VERSION ""

NS_ :

BS_:

BU_: DUT

BO_ 2365512363 MSG_DUT_FEDA: 16 DUT

BO_ 2558590718 MSG_DUT_8000: 8 DUT

BO_ 2559639294 MSG_DUT_9000: 52 DUT

BO_ 2365516715 MSG_DUT_COMP_ID: 13 DUT
 SG_ Component_ID_Delim_4 : 88|8@1+ (1,0) [0|65535] "" Vector__XXX
 SG_ Component_ID_Data_4 : 72|16@1+ (1,0) [0|65535] "" Vector__XXX
 SG_ Component_ID_Delim_3 : 64|8@1+ (1,0) [0|65535] "" Vector__XXX
 SG_ Component_ID_Data_3 : 48|16@1+ (1,0) [0|65535] "" Vector__XXX
 SG_ Component_ID_Delim_2 : 40|8@1+ (1,0) [0|65535] "" Vector__XXX
 SG_ Component_ID_Data_2 : 24|16@1+ (1,0) [0|65535] "" Vector__XXX
 SG_ Component_ID_Delim_1 : 16|8@1+ (1,0) [0|65535] "" Vector__XXX
 SG_ Component_ID_Data_1 : 0|16@1+ (1,0) [0|65535] "" Vector__XXX

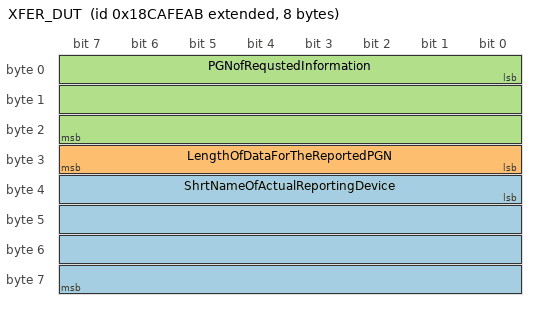
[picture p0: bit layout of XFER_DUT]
BO_ 2563440299 XFER_DUT: 8 DUT
 SG_ ShrtNameOfActualReportingDevice : 32|32@1+ (1,0) [0|0] "" Vector__XXX
 SG_ LengthOfDataForTheReportedPGN : 24|8@1+ (1,0) [0|255] "" Vector__XXX
 SG_ PGNofRequstedInformation : 0|24@1+ (1,0) [0|16777215] "" Vector__XXX

BO_ 2566834937 DM01_TOOL: 8 Vector__XXX
 SG_ DTC5 : 144|32@1+ (1,0) [0|4294967295] "" Vector__XXX
 SG_ DTC4 : 112|32@1+ (1,0) [0|4294967295] "" Vector__XXX
 SG_ DTC3 : 80|32@1+ (1,0) [0|4294967295] "" Vector__XXX
 SG_ DTC2 : 48|32@1+ (1,0) [0|4294967295] "" Vector__XXX
 SG_ DTC1 : 16|32@1+ (1,0) [0|4294967295] "" Vector__XXX
 SG_ FlashMalfuncIndicatorLamp : 14|2@1+ (1,0) [0|3] "" Vector__XXX
 SG_ FlashRedStopLamp : 12|2@1+ (1,0) [0|3] "" Vector__XXX
 SG_ FlashAmberWarningLamp : 10|2@1+ (1,0) [0|3] "" Vector__XXX
 SG_ FlashProtectLamp : 8|2@1+ (1,0) [0|3] "" Vector__XXX
 SG_ MalfunctionIndicatorLampStatus : 6|2@1+ (1,0) [0|3] "" Vector__XXX
 SG_ RedStopLampState : 4|2@1+ (1,0) [0|3] "" Vector__XXX
 SG_ AmberWarningLampStatus : 2|2@1+ (1,0) [0|3] "" Vector__XXX
 SG_ ProtectLampStatus : 0|2@1+ (1,0) [0|3] "" Vector__XXX

BO_ 2560758014 MSG_CYCLIC_NOREQ_DUT_A200: 8 Vector__XXX

BO_ 2560690942 MSG_CYCLIC_NOREQ_DUT_A100: 8 Vector__XXX

BO_ 2293563134 MSG_CYCLIC_DUT_B400: 17 Vector__XXX

BO_ 2562788094 MSG_CYCLIC_DUT_C100: 8 Vector__XXX

BO_ 2566785195 MSG_DUT_FE08: 22 DUT

BO_ 2566841598 MSG_DUT_FEE4: 80 Vector__XXX

BO_ 2566841259 MSG_DUT_FEE3: 16 DUT

BO_ 2561933054 MSG_DUT_B300: 16 Vector__XXX

BO_ 2561867518 MSG_DUT_B200: 1775 Vector__XXX

BO_ 2566841003 MSG_DUT_FEE2: 8 DUT

BO_ 2561801982 MSG_DUT_B100: 8 Vector__XXX

BO_ 2566840747 MSG_DUT_FEE1: 8 DUT

BO_ 2565406379 ACKM_DUT: 8 DUT
 SG_ AddressBusy m3 : 32|8@1+ (1,0) [0|255] "" Vector__XXX
 SG_ ControlByte M : 0|8@1+ (1,0) [0|255] "" Vector__XXX
 SG_ ParameterGroupNumber : 40|24@1+ (1,0) [0|16777215] "" Vector__XXX
 SG_ GroupFunctionValue : 8|8@1+ (1,0) [0|255] "" Vector__XXX
 SG_ AddressAccessDenied m2 : 32|8@1+ (1,0) [0|255] "" Vector__XXX
 SG_ AddressNegativeAcknowledgement m1 : 32|8@1+ (1,0) [0|255] "" Vector__XXX
 SG_ AddressAcknowledged m0 : 32|8@1+ (1,0) [0|255] "" Vector__XXX

BO_ 2565013246 MSG_DUT_E200: 8 Vector__XXX

BO_ 2566783403 MSG_DUT_FE01: 8 DUT

BO_ 2565799851 AC_DUT: 8 DUT
 SG_ ReservedBit : 48|1@1+ (1,0) [0|0] "" Vector__XXX
 SG_ ArbitraryAddressCapable : 63|1@1+ (1,0) [0|1] "" Vector__XXX
 SG_ IndustryGroup M : 60|3@1+ (1,0) [0|7] "" Vector__XXX
 SG_ VehicleSystemInstance : 56|4@1+ (1,0) [0|15] "" Vector__XXX
 SG_ Function : 40|8@1+ (1,0) [0|255] "" Vector__XXX
 SG_ FunctionInstance : 35|5@1+ (1,0) [0|31] "" Vector__XXX
 SG_ ECUInstance : 32|3@1+ (1,0) [0|7] "" Vector__XXX
 SG_ ManufacturerCode : 21|11@1+ (1,0) [0|2047] "" Vector__XXX
 SG_ IdentityNumber : 0|21@1+ (1,0) [0|2097152] "" Vector__XXX
 SG_ VehicleSystem m0 : 49|7@1+ (1,0) [0|127] "" Vector__XXX
 SG_ VehicleSystem5 m5 : 49|7@1+ (1,0) [0|127] "" Vector__XXX
 SG_ VehicleSystem4 m4 : 49|7@1+ (1,0) [0|127] "" Vector__XXX
 SG_ VehicleSystem3 m3 : 49|7@1+ (1,0) [0|127] "" Vector__XXX
 SG_ VehicleSystem2 m2 : 49|7@1+ (1,0) [0|127] "" Vector__XXX
 SG_ VehicleSystem1 m1 : 49|7@1+ (1,0) [0|127] "" Vector__XXX

CM_ "J1939 messages without part -7x";
CM_ BO_ 2563440299 "Transfer
The Transfer PGN provides a mechanism for reporting multiple data sets for a given PGN.";
CM_ SG_ 2563440299 ShrtNameOfActualReportingDevice "Subset of the 64-bit NAME (SPN 2848), consisting of the most significant 32 bits, which identifies the controller application.  It excludes the manufacturer code and identity number.  It is sometimes used to identify a device for instance in the ...";
CM_ SG_ 2563440299 LengthOfDataForTheReportedPGN "Length of data reported with the associated PGN via the Transfer PGN.";
CM_ SG_ 2563440299 PGNofRequstedInformation "PGN associated with this transfer message";
CM_ BO_ 2566834937 "Active Diagnostic Trouble Codes";
CM_ SG_ 2566834937 DTC1 "Diagnostic Trouble Code";
CM_ SG_ 2566834937 FlashMalfuncIndicatorLamp "This parameter provides the capability to flash the MIL
00 - Slow Flash (1 Hz, 50 % duty cycle)
01 - Fast Flash (2 Hz or faster, 50% duty cycle)
10 - Class C DTC
11 - Unavailable / Do Not Flash
Note:  State 10 is for WWH OBD discriminatory ...";
CM_ SG_ 2566834937 FlashRedStopLamp "This parameter provides the capability to flash the RSL


00 - Slow Flash (1 Hz, 50 % duty cycle)
01 - Fast Flash (2 Hz or faster, 50% duty cycle)
10 - Reserved
11 - Unavailable / Do Not Flash";
CM_ SG_ 2566834937 FlashAmberWarningLamp "This parameter provides the capability to flash the AWL

00 - Slow Flash (1 Hz, 50 % duty cycle)
01 - Fast Flash (2 Hz or faster, 50% duty cycle)
10 - Reserved
11 - Unavailable / Do Not Flash";
CM_ SG_ 2566834937 FlashProtectLamp "This parameter provides the capability to flash the engine protect lamp


00 - Slow Flash (1 Hz, 50 % duty cycle)
01 - Fast Flash (2 Hz or faster, 50% duty cycle)
10 - Reserved
11 - Unavailable / Do Not Flash";
CM_ SG_ 2566834937 MalfunctionIndicatorLampStatus "A lamp used to relay only emissions-related trouble code information. This lamp is only illuminated when there is an emission-related trouble code active.
00     Lamp Off
01     Lamp On
10     Short MIL for WWH OBD
11     Not available
Note ...";
CM_ SG_ 2566834937 RedStopLampState "This lamp is used to relay trouble code information that is of a severe enough condition that it warrants stopping the vehicle.

00     Lamp Off
01     Lamp On
10     Reserved
11     Not available";
CM_ SG_ 2566834937 AmberWarningLampStatus "This lamp is used to relay trouble code information that is reporting a problem with the vehicle system but the vehicle need not be immediately stopped. 

00     Lamp Off
01     Lamp On
10     Reserved
11     Not available";
CM_ SG_ 2566834937 ProtectLampStatus "This lamp is used to relay trouble code information that is reporting a problem with a vehicle system that is most probably not electronic subsystem related. For instance, engine coolant temperature is exceeding its prescribed temperature range.
00 ...";
CM_ BO_ 2565406379 "Acknowledgment Message
The Acknowledgment PG is used to provide a handshake mechanism between transmitting and receiving devices.";
CM_ SG_ 2565406379 ControlByte "Indicates the acknowledgement response.
0 - Positive Acknowledgment (ACK)
1 - Negative Acknowledgment (NACK)
2 - Access Denied (PGN supported but access denied)
3 - Cannot Respond (PGN supported but ECU cannot respond now) cannot respond with ...";
CM_ SG_ 2565406379 ParameterGroupNumber "PGN which is requested by the Request message";
CM_ SG_ 2565406379 GroupFunctionValue "Group Function of PGN being acknowledged. This field identifies for a device the specific group function of a PGN being acknowledged or declined.  This field is not used if the PGN being acknowledged or declined is not a group function PGN.";
CM_ BO_ 2565799851 "Address Claimed
Message used to claim an address for a Controller Application.";
CM_ SG_ 2565799851 ReservedBit "Reserved for future definition by SAE. The reserved bit shall be set to zero.";
CM_ SG_ 2565799851 IndustryGroup "0 = Global; 
   1  = On-Highway; 
   2  = Agricultural and Forestry; 
   3  = Construction; 
   4  = Marine;
   5  = Industrial - Process
          Control - Stationary (Gen-Sets)
   6  = Reserve for SAE
   7  = Reserve for SAE";
CM_ SG_ 2565799851 ManufacturerCode "Assigned by NMEA 2000 Committee";
BA_DEF_  "DBName" STRING ;
BA_DEF_ SG_  "SigType" ENUM  "Default","Range","RangeSigned","ASCII","Discrete","Control","ReferencePGN","DTC","StringDelimiter","StringLength","StringLengthControl","MessageCounter","MessageChecksum";
BA_DEF_ SG_  "GenSigStartValue" INT 0 2147483647;
BA_DEF_ SG_  "GenSigSendType" ENUM  "Cyclic","OnWrite","OnWriteWithRepetition","OnChange","OnChangeWithRepetition","IfActive","IfActiveWithRepetition","NoSigSendType";
BA_DEF_ SG_  "GenSigILSupport" ENUM  "No","Yes";
BA_DEF_ SG_  "GenSigEVName" STRING ;
BA_DEF_ SG_  "SPN" INT 0 524287;
BA_DEF_ BO_  "GenMsgStartDelayTime" INT 0 100000;
BA_DEF_ BO_  "GenMsgILSupport" ENUM  "No","Yes";
BA_DEF_ BO_  "GenMsgRequestable" INT 0 1;
BA_DEF_ BO_  "GenMsgSendType" ENUM  "cyclic","NotUsed","NotUsed","NotUsed","NotUsed","NotUsed","NotUsed","IfActive","noMsgSendType";
BA_DEF_ BO_  "VFrameFormat" ENUM  "StandardCAN","ExtendedCAN","reserved","J1939PG";
BA_DEF_ BO_  "GenMsgCycleTime" INT 0 3600000;
BA_DEF_ BU_  "NodeLayerModules" STRING ;
BA_DEF_ BU_  "NmStationAddress" INT 0 255;
BA_DEF_ BU_  "NmJ1939IndustryGroup" INT 0 7;
BA_DEF_ BU_  "NmJ1939System" INT 0 127;
BA_DEF_ BU_  "NmJ1939SystemInstance" INT 0 15;
BA_DEF_ BU_  "NmJ1939Function" INT 0 255;
BA_DEF_ BU_  "NmJ1939FunctionInstance" INT 0 7;
BA_DEF_ BU_  "NmJ1939ECUInstance" INT 0 3;
BA_DEF_ BU_  "NmJ1939ManufacturerCode" INT 0 2047;
BA_DEF_ BU_  "NmJ1939IdentityNumber" INT 0 2097151;
BA_DEF_  "SAE_J1939_DA_SpecVersion" STRING ;
BA_DEF_  "SAE_J1939_81_SpecVersion" STRING ;
BA_DEF_  "DatabaseVersion" STRING ;
BA_DEF_  "BusType" STRING ;
BA_DEF_  "ProtocolType" STRING ;
BA_DEF_  "SAE_J1939_21_SpecVersion" STRING ;
BA_DEF_DEF_  "DBName" "";
BA_DEF_DEF_  "SigType" "Default";
BA_DEF_DEF_  "GenSigStartValue" 0;
BA_DEF_DEF_  "GenSigSendType" "NoSigSendType";
BA_DEF_DEF_  "GenSigILSupport" "Yes";
BA_DEF_DEF_  "GenSigEVName" "Env@Nodename_@Signame";
BA_DEF_DEF_  "SPN" 0;
BA_DEF_DEF_  "GenMsgStartDelayTime" 0;
BA_DEF_DEF_  "GenMsgILSupport" "Yes";
BA_DEF_DEF_  "GenMsgRequestable" 1;
BA_DEF_DEF_  "GenMsgSendType" "noMsgSendType";
BA_DEF_DEF_  "VFrameFormat" "J1939PG";
BA_DEF_DEF_  "GenMsgCycleTime" 0;
BA_DEF_DEF_  "NodeLayerModules" "";
BA_DEF_DEF_  "NmStationAddress" 254;
BA_DEF_DEF_  "NmJ1939IndustryGroup" 0;
BA_DEF_DEF_  "NmJ1939System" 0;
BA_DEF_DEF_  "NmJ1939SystemInstance" 0;
BA_DEF_DEF_  "NmJ1939Function" 0;
BA_DEF_DEF_  "NmJ1939FunctionInstance" 0;
BA_DEF_DEF_  "NmJ1939ECUInstance" 0;
BA_DEF_DEF_  "NmJ1939ManufacturerCode" 0;
BA_DEF_DEF_  "NmJ1939IdentityNumber" 0;
BA_DEF_DEF_  "SAE_J1939_DA_SpecVersion" "";
BA_DEF_DEF_  "SAE_J1939_81_SpecVersion" "";
BA_DEF_DEF_  "DatabaseVersion" "";
BA_DEF_DEF_  "BusType" "";
BA_DEF_DEF_  "ProtocolType" "";
BA_DEF_DEF_  "SAE_J1939_21_SpecVersion" "";
BA_ "SAE_J1939_DA_SpecVersion" "2015-01";
BA_ "SAE_J1939_81_SpecVersion" "2012-05";
BA_ "DatabaseVersion" "8.5";
BA_ "BusType" "CAN";
BA_ "ProtocolType" "J1939";
BA_ "SAE_J1939_21_SpecVersion" "2006-10";
BA_ "DBName" "J1939_CT_Demo";
BA_ "NodeLayerModules" BU_ DUT "J1939_IL.vmodule";
BA_ "NmStationAddress" BU_ DUT 171;
BA_ "NmJ1939IndustryGroup" BU_ DUT 4;
BA_ "NmJ1939System" BU_ DUT 20;
BA_ "NmJ1939SystemInstance" BU_ DUT 11;
BA_ "NmJ1939Function" BU_ DUT 13;
BA_ "NmJ1939FunctionInstance" BU_ DUT 1;
BA_ "NmJ1939ECUInstance" BU_ DUT 2;
BA_ "NmJ1939ManufacturerCode" BU_ DUT 1861;
BA_ "NmJ1939IdentityNumber" BU_ DUT 12345;
BA_ "GenMsgSendType" BO_ 2558590718 0;
BA_ "GenMsgCycleTime" BO_ 2558590718 40;
BA_ "GenMsgRequestable" BO_ 2560758014 0;
BA_ "GenMsgSendType" BO_ 2560758014 0;
BA_ "GenMsgCycleTime" BO_ 2560758014 1000;
BA_ "GenMsgRequestable" BO_ 2560690942 0;
BA_ "GenMsgSendType" BO_ 2560690942 0;
BA_ "GenMsgCycleTime" BO_ 2560690942 900;
BA_ "GenMsgStartDelayTime" BO_ 2293563134 1500;
BA_ "GenMsgSendType" BO_ 2293563134 0;
BA_ "GenMsgCycleTime" BO_ 2293563134 3000;
BA_ "GenMsgSendType" BO_ 2562788094 0;
BA_ "GenMsgCycleTime" BO_ 2562788094 100;
BA_ "GenMsgCycleTime" BO_ 2566841003 100;
BA_ "GenMsgSendType" BO_ 2566841003 0;
BA_ "GenMsgRequestable" BO_ 2565406379 0;
BA_ "GenMsgSendType" BO_ 2566783403 0;
BA_ "GenMsgCycleTime" BO_ 2566783403 777;
BA_ "GenSigStartValue" SG_ 2365516715 Component_ID_Delim_4 42;
BA_ "GenSigStartValue" SG_ 2365516715 Component_ID_Data_4 1028;
BA_ "GenSigStartValue" SG_ 2365516715 Component_ID_Delim_3 42;
BA_ "GenSigStartValue" SG_ 2365516715 Component_ID_Data_3 771;
BA_ "GenSigStartValue" SG_ 2365516715 Component_ID_Delim_2 42;
BA_ "GenSigStartValue" SG_ 2365516715 Component_ID_Data_2 514;
BA_ "GenSigStartValue" SG_ 2365516715 Component_ID_Delim_1 42;
BA_ "GenSigStartValue" SG_ 2365516715 Component_ID_Data_1 257;
BA_ "SigType" SG_ 2563440299 ShrtNameOfActualReportingDevice 4;
BA_ "SPN" SG_ 2563440299 ShrtNameOfActualReportingDevice 2554;
BA_ "SigType" SG_ 2563440299 LengthOfDataForTheReportedPGN 1;
BA_ "SPN" SG_ 2563440299 LengthOfDataForTheReportedPGN 2553;
BA_ "SigType" SG_ 2563440299 PGNofRequstedInformation 6;
BA_ "SPN" SG_ 2563440299 PGNofRequstedInformation 2552;
BA_ "SPN" SG_ 2565406379 AddressBusy 3293;
BA_ "SigType" SG_ 2565406379 ControlByte 6;
BA_ "SPN" SG_ 2565406379 ControlByte 2541;
BA_ "SigType" SG_ 2565406379 ParameterGroupNumber 6;
BA_ "SPN" SG_ 2565406379 ParameterGroupNumber 2547;
BA_ "SigType" SG_ 2565406379 GroupFunctionValue 1;
BA_ "SPN" SG_ 2565406379 AddressAccessDenied 3292;
BA_ "SPN" SG_ 2565406379 AddressNegativeAcknowledgement 3291;
BA_ "SPN" SG_ 2565406379 AddressAcknowledged 3290;
BA_ "SPN" SG_ 2565799851 ArbitraryAddressCapable 2844;
BA_ "SPN" SG_ 2565799851 IndustryGroup 2846;
BA_ "SPN" SG_ 2565799851 VehicleSystemInstance 2843;
BA_ "SPN" SG_ 2565799851 Function 2841;
BA_ "SPN" SG_ 2565799851 FunctionInstance 2839;
BA_ "SPN" SG_ 2565799851 ECUInstance 2840;
BA_ "SigType" SG_ 2565799851 ManufacturerCode 1;
BA_ "SPN" SG_ 2565799851 ManufacturerCode 2838;
BA_ "SPN" SG_ 2565799851 IdentityNumber 2837;
VAL_ 2565406379 ControlByte 3 "Cannot Respond" 2 "Access Denied" 1 "Negative Acknowledgment" 0 "Positive Acknowledgment" ;
VAL_ 2565799851 IndustryGroup 6 "Reserved for SAE" 7 "Reserved for SAE" 5 "IndustrialProcessCtrlStationary" 4 "Marine" 3 "Construction" 2 "Agricultural and Forestry" 1 "On-Highway" 0 "Global" ;
VAL_ 2565799851 Function 127 "Reserved" 126 "Reserved" 125 "Reserved" 124 "Reserved" 123 "Reserved" 122 "Reserved" 121 "Reserved" 120 "Reserved" 119 "Reserved" 118 "Reserved" 117 "Reserved" 116 "Reserved" 115 "Reserved" 114 "Reserved" 113 "Reserved" 112 "Reserved" 111 "Reserved" 110 "Reserved" 109 "Reserved" 108 "Reserved" 107 "Reserved" 106 "Reserved" 105 "Reserved" 104 "Reserved" 103 "Reserved" 102 "Reserved" 101 "Reserved" 42 "Water Pump Control" 41 "Lighting - Operator Controls" 40 "Seat Control" 39 "Ignition Control Module" 38 "Tire Pressure Control" 37 "Cab Controller" 36 "Pneumatic - System Controller" 35 "Suspension - System Controller" 34 "Hydraulic Pump Controller" 33 "System Monitor" 32 "Headway Controller" 31 "Propulsion Battery Charger" 30 "Management Computer" 29 "Virtual Terminal (in cab)" 28 "Off Vehicle Gateway" 27 "Power TakeOff (Secondary or Front)" 26 "Body Controller" 25 "Network Interconnect ECU" 24 "Vehicle Security" 23 "Vehicle Navigation" 22 "Aerodynamic Control" 21 "Cab Climate Control" 20 "Trip Recorder" 19 "Instrument Cluster" 18 "Suspension - Drive Axle" 17 "Suspension - Steer Axle" 16 "Steering Controller" 15 "Fuel System" 14 "Cruise Control" 13 "Retarder - Driveline" 12 "Retarder - Engine" 11 "Brakes - Drive Axle" 10 "Brakes - Steer Axle" 9 "Brakes - System Controller" 8 "Axle - Drive" 7 "Axle - Steering" 6 "Power TakeOff - (Main or Rear)" 5 "Shift Control/Console" 4 "Battery Pack Monitor" 3 "Transmission" 2 "Electric Propulsion Control" 1 "Auxiliary Power Unit (APU)" 0 "Engine" 100 "Reserved" 99 "Reserved" 98 "Reserved" 97 "Reserved" 96 "Reserved" 95 "Reserved" 94 "Reserved" 93 "Reserved" 92 "Reserved" 91 "Reserved" 90 "Reserved" 89 "Reserved" 88 "Reserved" 87 "Reserved" 86 "Reserved" 85 "Reserved" 84 "Reserved" 83 "Reserved" 82 "Reserved" 81 "Reserved" 80 "Reserved" 79 "Reserved" 78 "Fire Suppression System" 77 "Fuel Properties Sensor" 76 "Temperature Sensor" 75 "Supplemental Fan" 74 "Lubrication System" 73 "Rollover Detection Control" 72 "Coolant Valve Controller" 71 "Transfer Case Control" 70 "Auxiliary Regeneration Device" 69 "Engine Emission Aftertreatement System" 68 "Aftertreatment system gas measurement" 67 "Electrical System Controller" 66 "I/O Controller" 65 "Gas Flow Measurement" 64 "Endurance Braking" 63 "Engine Valve Controller" 62 "On-Board Diagnostic Unit" 61 "File Server/Printer" 60 "Cab Display" 59 "Starter" 58 "Fan Drive Control" 57 "Steering Column Unit" 56 "Communications Unit, Radio" 55 "Communications Unit, Satellite" 54 "Communications Unit, Cellular" 53 "Alternator/Charging System" 52 "Chassis Controller" 51 "Forward-Looking Collision Warning System" 50 "Auxiliary Heater" 49 "Clutch/Converter Control" 48 "Ramp Control" 47 "Information System Controller" 46 "Oil Sensor Unit" 45 "Vehicle Dynamic Stability Control" 44 "Exhaust Emission Control" 43 "Transmission Display" ;
VAL_ 2565799851 ManufacturerCode 454 "NGK Spark Plug Co. Ltd" 453 "Cooper Bussmann" 452 "WIKA Alexander Wiegand SE & Co. KG" 451 "Parker Hannifin Corp" 450 "Dycor Technologies Ltd." 449 "Polaris Industries Inc" 448 "Stanadyne Corporation, Electronics Systems" 447 "Great Plains Mfg." 446 "CertTech, L.L.C." 445 "KAT MECHATRONIC, Electronic Product Division" 444 "ITT Power Solutions" 443 "SignalQuest, Inc." 442 "Horsch Maschinen GmbH" 441 "PTG Reifendruckregelsysteme GmbH" 440 "Cummins Power Generation" 439 "Hyundai Heavy Industries" 438 "Comar Systems Ltd" 437 "Digital Yacht Limited" 436 "Kinze Manufacturing" 435 "Zunhammer GmbH" 434 "Stored Energy Systems" 433 "Rowe Electronics" 432 "S&A Systems, Inc." 431 "Tohatsu Corporation" 430 "Auteq Telematica S.A." 520 "Trapeze" 519 "Peeters Landbouwmachines b.v." 518 "Transas USA Inc." 517 "Noland Engineering" 516 "AVAT Automation GmbH" 515 "GINAF Trucks Nederland B.V." 514 "DISTek Integration, Inc." 513 "FarmscanAg" 512 "Inpower LLC" 511 "Sulky" 510 "Marinesoft Co. Ltd" 509 "MOTORTECH GmbH" 508 "Transtech Innovations" 507 "Test Center ISOBUS" 506 "IHI STAR Machinery Corporation" 505 "Yetter Farm Equipment" 504 "Vesper Marine" 503 "Naviop S.R.L." 502 "Attwood Corporation" 501 "Agrotronix S.A." 500 "Oxbo International Corporation" 499 "LCJ Capteurs" 498 "Innovative Design Solutions, Inc" 497 "SENTRON Sistemas Embarcados" 496 "W. Gessmann GmbH" 495 "HOLMER Maschinenbau GmbH" 494 "Synerject" 493 "Watcheye" 492 "Inergy Automotive Systems" 491 "Penny and Giles Ltd" 490 "QuikQ" 489 "Appareo Systems" 488 "The Charles Machine Works, Inc." 487 "DSE Test Solutions A/S" 486 "Westport Innovations Inc." 485 "MATT automotive" 484 "Headsight Inc." 483 "Valeo" 482 "Tricon Electronics" 481 "Chetco Digital Instruments" 480 "EnerDel, Inc." 479 "Vapor Bus International" 478 "OceanSat BV" 477 "OilQuick AB" 476 "Hummingbird Marine Electronics" 475 "GME" 474 "Persen Technologies Inc." 473 "Boss Industries, Inc." 472 "Tenneco Inc." 471 "Sea Cross Marine AB" 470 "SI-TEX Marine Electronics" 469 "RA Consulting GmbH" 468 "Tyco Fire Protection Products" 467 "Lely Industries N.V." 466 "Veethree Electronics and Marine LLC" 465 "Ashcroft Inc" 464 "Leach International Corporation" 463 "PROBOTIQ" 462 "IHI Shibaura Machinery Corporation" 461 "HAWE Hydraulik SE" 460 "San Giorgio S.E.I.N." 459 "Alltek Marine Electronics Corp" 458 "Control Solutions, Inc." 457 "RUSELPROM-ElectricDrive Ltd" 456 "General Kinetics" 455 "ADZ NAGANO GmbH" 429 "Rota Engineering Ltd." 428 "Mfg_428" 427 "em-trak Marine Electronics Ltd" 426 "Egersund Marine Electronics AS" 425 "Methode Electronics Inc, MDI" 424 "Odyne LLC" 423 "BSM Wireless, Inc." 422 "True Heading AB" 421 "Vertex Standard Co, Ltd" 420 "Vermeer Corporation, ACS Group" 419 "Fusion Electronics Ltd" 418 "Intellistick Inc" 417 "KZValve" 416 "Kubota Corporation" 415 "Valid Manufacturing Ltd." 414 "Cattron Group International" 413 "Datapross Nijbroek bv" 412 "WebTech Wireless Inc." 411 "Hy-Drive Technologies Ltd." 410 "COBO S.p.A. Divisione 3B6" 409 "Transfluid S.r.L." 408 "Corvus Energy Ltd." 407 "Comtech Mobile Datacom" 406 "Vecima Networks Inc." 405 "Wema System AS" 404 "Com Nav Marine Ltd" 403 "Trackwell ADS, Inc." 402 "Simma Software, Inc." 401 "Torqeedo GmbH" 400 "Livorsi Marine" 399 "ISEKI & Co., Ltd." 398 "Hilite International" 397 "Sanyo-kiki Co Ltd." 396 "Beyond Measure" 395 "GENTEC S.R.L." 394 "Capi 2 Nederland BV" 393 "Harvest Tec, Inc" 392 "Tianyuan Technology Co Ltd." 391 "Electronic Design for Industry, Inc" 390 "Partech Inc." 389 "Benchmark Electronics, Minnesota Division" 388 "Innomatix, LLC" 387 "Orscheln Products, LLC" 386 "JLG Automation BVBA" 385 "Johnson Outdoor Marine Electronics" 384 "Camano Light" 383 "MCL Industries" 382 "National Agricultural and Food Research Organization" 380 "Suntech International Ltd." 379 "Yamabiko Corporation" 378 "Glendinning Marine Products" 377 "ifm electronic gmbh" 376 "Quake Global" 375 "Williams Controls Inc." 372 "Delphi" 381 "B&G" 374 "Northern Lights, Inc." 373 "Electronic Design Inc." 371 "Heinzmann GmbH & Co. KG" 370 "Rolls-Royce Marine AS" 369 "Power Torque Engineering Ltd" 368 "HANSENHOF_electronic" 367 "Fliegl Agrartechnik" 366 "Viewnyx Corp." 365 "Digi-Star, LLC" 364 "OEM Controls Inc." 363 "BEI Duncan" 362 "Alois Poettinger Maschinenfabrik GmbH" 361 "InMach" 360 "HJS Emission Technology GmbH & Co KG" 359 "Ludwig Bergmann GmbH" 358 "Victron Energy BV" 357 "Hardi International A/S" 356 "Fischer Panda Generators, Inc" 355 "Mastervolt International B.V." 354 "Junkkari OY" 353 "Hegemon Electronics, Inc." 352 "SAME DEUTZ-FAHR" 351 "Thrane & Thrane" 350 "Noris Marine Systems GmbH & Co KG" 349 "Suonentiet" 348 "Amazonen Werke H. Dreyer" 347 "Honeywell" 346 "Control Solutions" 345 "Korean Maritime University" 344 "Parvus Corporation" 343 "Baumer Group" 342 "THOMAS MAGNETE GmbH" 341 "Boning GmbH & Co" 340 "Continental AG" 339 "Competence Center ISOBUS e.V." 338 "GRAF-SYTECO" 337 "Carraro S.p.A." 336 "APE s.r.o." 335 "Evo Electric Ltd" 334 "Takata-Petri AG" 333 "Hadley Products Corporation" 332 "HWH Corporation" 331 "Horton, Inc." 330 "Kidde Aerospace and Defense" 329 "Deif A/S" 328 "Qwerty Electronik AB" 252 "Sensor-Technik Wiedemann GmbH" 251 "German Agricultural Society" 250 "Kuhn Group" 249 "Schaltbau GmbH" 233 "Yacht Monitoring Solutions Inc." 232 "TSD Integrated Controls" 1863 "Thomas G. Faria Co." 1862 "Sanshin" 1861 "Vector CANtech" 1860 "MMP" 1859 "Kvasar AB" 1858 "Litton" 1857 "Simrad" 1856 "Trimble" 1855 "Furuno USA" 1854 "Northstar Technologies" 1853 "Japan Radio Co." 1852 "Navionics" 1851 "Raymarine" 1850 "Teleflex" 222 "Generac Power Systems, Inc." 221 "SiE" 220 "Beede Electrical Instrument Company, Inc." 219 "Cat OEM Solutions" 218 "Gits Manufacturing Company" 217 "RM Michaelides Software & Elektronik GmbH" 216 "Paneltronics Inc." 215 "Aetna Engineering/Fireboy-Xintex" 214 "MC elettronica Srl" 213 "CNH Belgium N.V." 212 "Sure Power Industries, Inc." 211 "DNA Group" 210 "Iteris, Inc." 209 "Bell Equip. Co. SA (PTY) LTD" 208 "Drew Technologies, Inc." 207 "Otto Engineering" 206 "port GmbH" 205 "SmarTire Systems Inc" 204 "The Morey Corporation" 203 "MILtronik GmbH" 202 "Curtis Instruments, Inc." 201 "Disenos y Tecnologia S.A." 200 "MGM Brakes" 199 "Actia Corp." 198 "Mystic Valley Communications" 197 "Mechron Power Systems" 196 "LEMKEN GmbH & Co. KG" 195 "General Engine Products" 194 "TriMark Corporation" 193 "Nobletec" 192 "Floscan" 191 "XRS Corporation" 190 "Hella KGaA Hueck & Co." 189 "QUALCOMM" 188 "EMP Corp." 187 "Air-Weigh" 186 "Altronic, Inc." 185 "Beede Electrical Instrument Company" 184 "EIA Electronics" 183 "KDS Controls, Inc." 182 "Vehicle Systems Engineering B.V." 181 "Coretronics, Inc." 180 "Smart Power Systems" 179 "TeeJet Technologies Denmark" 178 "Siemens VDO Automotive AG" 177 "Diagnostic System Associates" 176 "Moritz Aerospace" 175 "Veris Technologies, Inc." 174 "AB Volvo Penta" 173 "Ryeso, Inc." 172 "Yanmar Marine USA" 171 "Wachendorff Elektronik GmbH & Co. KG" 170 "Computronics Corporation Ltd." 169 "Marlin Technologies Inc." 168 "Xantrex" 167 "JLG Industries Inc." 166 "Phoenix International" 165 "CPAC Systems AB" 164 "DaimlerChrysler Off-Highway" 163 "BRP Inc." 162 "Axiomatic Technologies" 161 "Offshore Systems (UK) Limited" 160 "Nido" 159 "NTech Industries Inc." 158 "Firestone Industrial Products Company" 157 "ISSPRO Inc." 156 "ITT Industries - Cannon" 155 "Vetronix Corporation" 154 "Westerbeke Corporation" 153 "Woodward, Industrial Controls Division" 152 "elobau GmbH & Co. KG" 151 "Raven Industries Inc. - Flow Controls Division" 150 "Fleetguard" 149 "Holset" 148 "Blue Water Data, Inc." 147 "Nautibus Electronic GmbH" 146 "Maxima Technologies" 145 "MurCal Controls" 144 "Mercury Marine" 143 "W. Gmeiner GmbH & Co." 142 "TRW Automotive (Commercial Steering Systems)" 141 "Thales Navigation Ltd." 140 "Lowrance Electronics, Inc." 139 "Caterpillar Trimble Control Technologies (CTCT), LLC" 138 "Georg Fritzmeier GmbH & Co. KG" 137 "Maretron" 136 "Komatsu Ltd." 135 "Airmar Technology Corporation" 134 "Iris Technology Ltd." 133 "Bucher Schoerling GmbH" 132 "Mulag-Fahrzeugwerk" 131 "ITT Industries" 130 "Nido - Universal Machines B.V." 129 "OMNEX Control Systems, Inc." 128 "Gerhard Duecker GmbH & Co. KG" 127 "Holland USA" 126 "Driver Tech" 125 "Nevada Automotive Test Center" 124 "Hydac Electronic" 123 "Basler Electric" 122 "FG Wilson (Engineering) Limited" 121 "HED (Hydro Electronic Devices, Inc.)" 120 "RDS Technology Ltd." 119 "IntegriNautics" 118 "Intron GmbH" 117 "HUSCO International" 116 "BEELINE Technologies" 115 "NACCO Materials Handling Group, Inc." 114 "EControls, Inc." 113 "Stress-Tek, Inc." 112 "MECALAC" 111 "Maschinenfabrik Bernard Krone GmbH" 110 "EPIQ Sensor-Nite" 109 "TeeJet Technologies Denmark" 108 "WTK-Elecktronik GmbH" 107 "Grimme Landmaschinen GmbH & Co. KG" 106 "BAE Systems Controls, Inc." 105 "Kiepe Elektrik GmbH & Co. KG" 104 "Claas Selbstfahrende Erntemaschinen GmbH" 103 "CLAAS Agrosystems GmbH & Co. KG" 102 "AGCO GmbH & Co." 101 "Sensoria" 100 "VDO Technik AG" 99 "International Transmissions Ltd (ITL)" 98 "Mueller-Elektronik GmbH & Co." 97 "Ag Leader Technology, Inc." 96 "Mech@tronic IT GmbH" 95 "Pacific Insight Electronics Corp." 94 "CNH Global N.V." 93 "Perkins Engines Company Ltd." 92 "Ag-Chem Equipment Co., Inc." 91 "BSG Bodensee Steuergeraete GmbH" 90 "Knorr-Bremse SfN GmbH" 89 "Kverneland Group, Electronics Division" 88 "Satloc Precision GPS" 87 "J.C. Bamford Excavators Ltd (JCB)" 86 "C.E. Niehoff & Company" 85 "Kohler Co." 84 "New Holland UK Limited" 83 "Bendix VORAD Technologies" 82 "Bobcat/Ingersoll-Rand" 81 "Fire Research Corp" 80 "Twin Disc, Inc." 79 "Daimler Benz AG - Engine Division (PBM)" 78 "Frank W. Murphy Manufacturing, Inc." 77 "Deere Power Systems Group" 76 "unused" 75 "Deere & Co. Agricultural Division" 74 "Eaton Axle-Brake Division" 73 "LeTourneau, Inc." 72 "Sisu Corporation" 71 "Vansco Electronics Ltd." 70 "Flex-Coil Limited" 69 "Trimble Navigation" 68 "Scania" 67 "Funk Manufacturing Company" 66 "John Deere Construction Equipment Division" 65 "MAN Nutzfahrzeuge AG" 64 "unused" 63 "ZF Industries Inc." 62 "Wabco" 61 "Volvo Truck Corp." 60 "Volvo Trucks North America Inc." 59 "VES Inc." 58 "SPX Corporation, OTC Division" 57 "Sauer-Danfoss Co." 56 "SAIC" 55 "Ryder System Inc." 54 "Meritor Wabco" 53 "Continental Automotive Systems US, Inc." 52 "Meritor Automotive, Inc." 51 "Robert Bosch GmbH" 50 "Robert Bosch Corp" 49 "RE America Inc." 48 "Pollak Alphabet" 47 "Phillips Semiconductor" 46 "Noregon Systems, Inc" 45 "PACCAR" 44 "Nippondenso Co. Ltd." 43 "International Truck and Engine Corp. Vehicle Electronics" 42 "International Truck and Engine Corp. Engine Electronics" 41 "Motorola Inc." 40 "Motorola AIEG Inc." 39 "Microfirm Inc." 38 "Micro Processor Systems Inc." 37 "Mack Trucks Inc." 36 "Lucas Ltd." 35 "Kenworth Truck Co." 34 "Kelsey Hayes Co." 33 "John Deere" 32 "Jacobs Vehicle Systems" 31 "J Pollak Corp." 30 "Isuzu Motors Ltd." 29 "Hino Motors Ltd." 28 "Grote Ind. Inc." 27 "GMC" 26 "General Motors Corp., Service Technology Group" 25 "Daimler Trucks North America LLC" 24 "Ford Motor Co., Vehicle Controls" 23 "Ford Motor Co., Heavy Truck" 22 "Ford Motor Co., Electronic Concepts $ Systems" 21 "Echilin Inc., Midland Brake Inc." 20 "Eaton Ltd" 19 "Eaton Corp. Trucking Info Services" 18 "Eaton Corp, Transmission Division" 17 "Eaton Corp. Res & Dev" 16 "Eaton Corp." 15 "Dickey-John Corp." 14 "Detroit Diesel Corporation" 13 "Delco Electronics" 12 "Deere & Company, Precision Farming" 11 "Dearborn Group Inc." 10 "Cummins Engine Co." 9 "Chrysler Corp." 8 "Caterpillar Inc." 7 "Case Corp." 6 "Berifors Electronics AB" 5 "AMP Inc." 4 "Ametek-Dixson" 3 "Ametek, US Gauge Division" 2 "Allison Transmission, GMC" 1 "Allied Signal Inc." 0 "Reserved" 231 "Topcon Positioning Systems, Inc." 230 "Saucon Technologies" 229 "Garmin International Inc." 228 "ZF Marine Electronics" 227 "Lykketronic A/S" 226 "Monaco Coach Corporation" 225 "SKF" 224 "EMMI Network, S.L." 223 "Vaueo Retarder Co., Ltd." 263 "IMMI" 262 "HydraForce, Inc" 261 "Red Dot Corporation" 260 "Reichhardt GmbH" 259 "Jetter AG" 258 "ARAG" 257 "Honda Motor Co., Ltd" 256 "Tyco Electronics AMP" 255 "MEAS France" 254 "GE Sensing" 253 "Mobile Control Systems" 298 "Holley Performance" 297 "Zonar Systems Inc" 296 "micro dynamics GmbH" 295 "BEP Marine" 294 "Grayhill Inc." 293 "Spyder Controls Corp." 292 "IKUSI - Angel Iglesias S.A." 291 "Groeneveld Transport Efficiency BV" 290 "Kuebler GmbH" 289 "Watlow" 288 "Mitsubishi FUSO Truck & Bus Corp." 287 "NTech Industries, Inc" 286 "Coelmo srl" 285 "Sea Recovery Corp" 284 "Mobile Tech Chile" 283 "CWF Hamilton & Co Ltd" 282 "Medallion Instrumentation Systems" 281 "Precision Governors LLC" 311 "Patrick Power Products" 310 "TECNORD srl" 309 "Krauss-Maffei Wegmann GmbH & Co. KG" 308 "Cyntrx" 307 "MBW Technologies" 306 "Sleipner Motor AB" 305 "NovAtel Inc" 304 "EmpirBus AB" 303 "CTS Corporation" 302 "Nissin Kogyo Co., LTD" 301 "Parker Hannifin (UK) Ltd FDE group" 300 "Systron Donner Automotive" 299 "Rauch Landmaschinen GmbH" 280 "Leica Geosystems Pty Ltd" 279 "Geometris LP" 278 "Takata Electronics" 277 "LHP Telematics" 276 "Aqua-Hot Heating Systems" 275 "Navico Egersund AS" 274 "LTW Technology Co., LTD" 273 "Active Research Limited" 272 "Gross Mechanical Laboratories, Inc" 327 "Sonceboz SA" 326 "Akron Brass Company" 325 "ASM Automation Sensorik Messtechnik GmbH" 324 "Snap-on Diagnostics" 323 "Mobileye Vision Technologies Ltd." 322 "MICHENKA s.r.o." 321 "Ultra Electronics, Electrics" 320 "Miedema Landbouwwerktuigenfabriek B.V." 319 "Cadec Global" 318 "SAT Plan" 317 "Navtronics Bvba" 316 "ITT Flow Control" 315 "Icom Incorporated" 314 "CSM GmbH" 313 "Ilmor Engineering, Inc" 312 "Lectronix, Inc." 271 "Cole Hersee" 270 "Tennant" 269 "Saft America Inc.,  Space & Defense Division" 268 "Accurate Technologies" 267 "Red Lion Controls, Inc" 266 "International Thermal Research Ltd" 265 "MTS Sensor Technologie GmbH" 264 "Autolync" 248 "Cooper Standard Automotive Active Systems Group" 247 "ePULSE" 246 "Class 1, Inc" 245 "Capstan Ag Systems, Inc." 244 "Techno-Matic" 243 "eRide, Inc." 242 "Kokusandenki Co. Ltd" 241 "Schneider Automation SAS " 240 "Vanair Mfg" 239 "May & Scofield Ltd" 238 "ZF Friedrichshafen AG" 237 "Agtron Enterprises Inc" 236 "Norac Systems International Inc" 235 "SailorMade Marine Telemetry - Tetra Technology Ltd." 234 "Mondial electronic GmbH" ;
VAL_ 2565799851 VehicleSystem 0 "Non-specific System" 127 "Not Available" ;
VAL_ 2565799851 VehicleSystem5 127 "Not Available" 0 "Ind. Process Control Stationary" ;
VAL_ 2565799851 VehicleSystem4 125 "Entertainment" 120 "Display" 85 "External Environment" 75 "Sensor Communication Interface" 35 "Electrical Generation" 100 "Deck, Cargo and Fishing Equipment" 90 "Internal Environment" 80 "Instrumentation/General Systems (deprecate)" 70 "Communications" 60 "Navigation" 50 "Propulsion" 40 "Steering and Control Surfaces" 30 "Electrical Distribution" 25 "Inter/Intranetwork Device" 20 "Safety Systems" 10 "System Tools" 127 "Not Available" 0 "Non-specific System" ;
VAL_ 2565799851 VehicleSystem3 8 "Grader" 7 "Four Wheel Drive Loader" 6 "Forklift" 5 "Excavator" 4 "Crawler" 3 "Backhoe" 2 "Articulated Dump Truck" 1 "Skid Steer Loader" 127 "Not Available" 0 "Non-specific System" ;
VAL_ 2565799851 VehicleSystem2 25 "Slurry Applicators" 24 "Utility Vehicles" 23 "Mulchers" 22 "Timber Processing Machines" 21 "Timber loaders" 20 "Forwarders" 19 "Timber Harvesters" 17 "Sensor Systems" 16 "Skidder" 15 "Earth Work" 14 "Special Crops" 13 "Powered Auxiliary Device" 12 "Farm Yard Operations" 11 "Transport/Trailer" 10 "Irrigation" 9 "Forage" 8 "Root Harvesters" 7 "Harvesters" 6 "Sprayers" 5 "Fertilizers" 4 "Planters/Seeders" 3 "Secondary Tillage" 2 "Tillage" 1 "Tractor" 127 "Not Available" 0 "Non-specific System" ;
VAL_ 2565799851 VehicleSystem1 2 "Trailer" 1 "Tractor" 127 "Not Available" 0 "Non-specific System" ;
